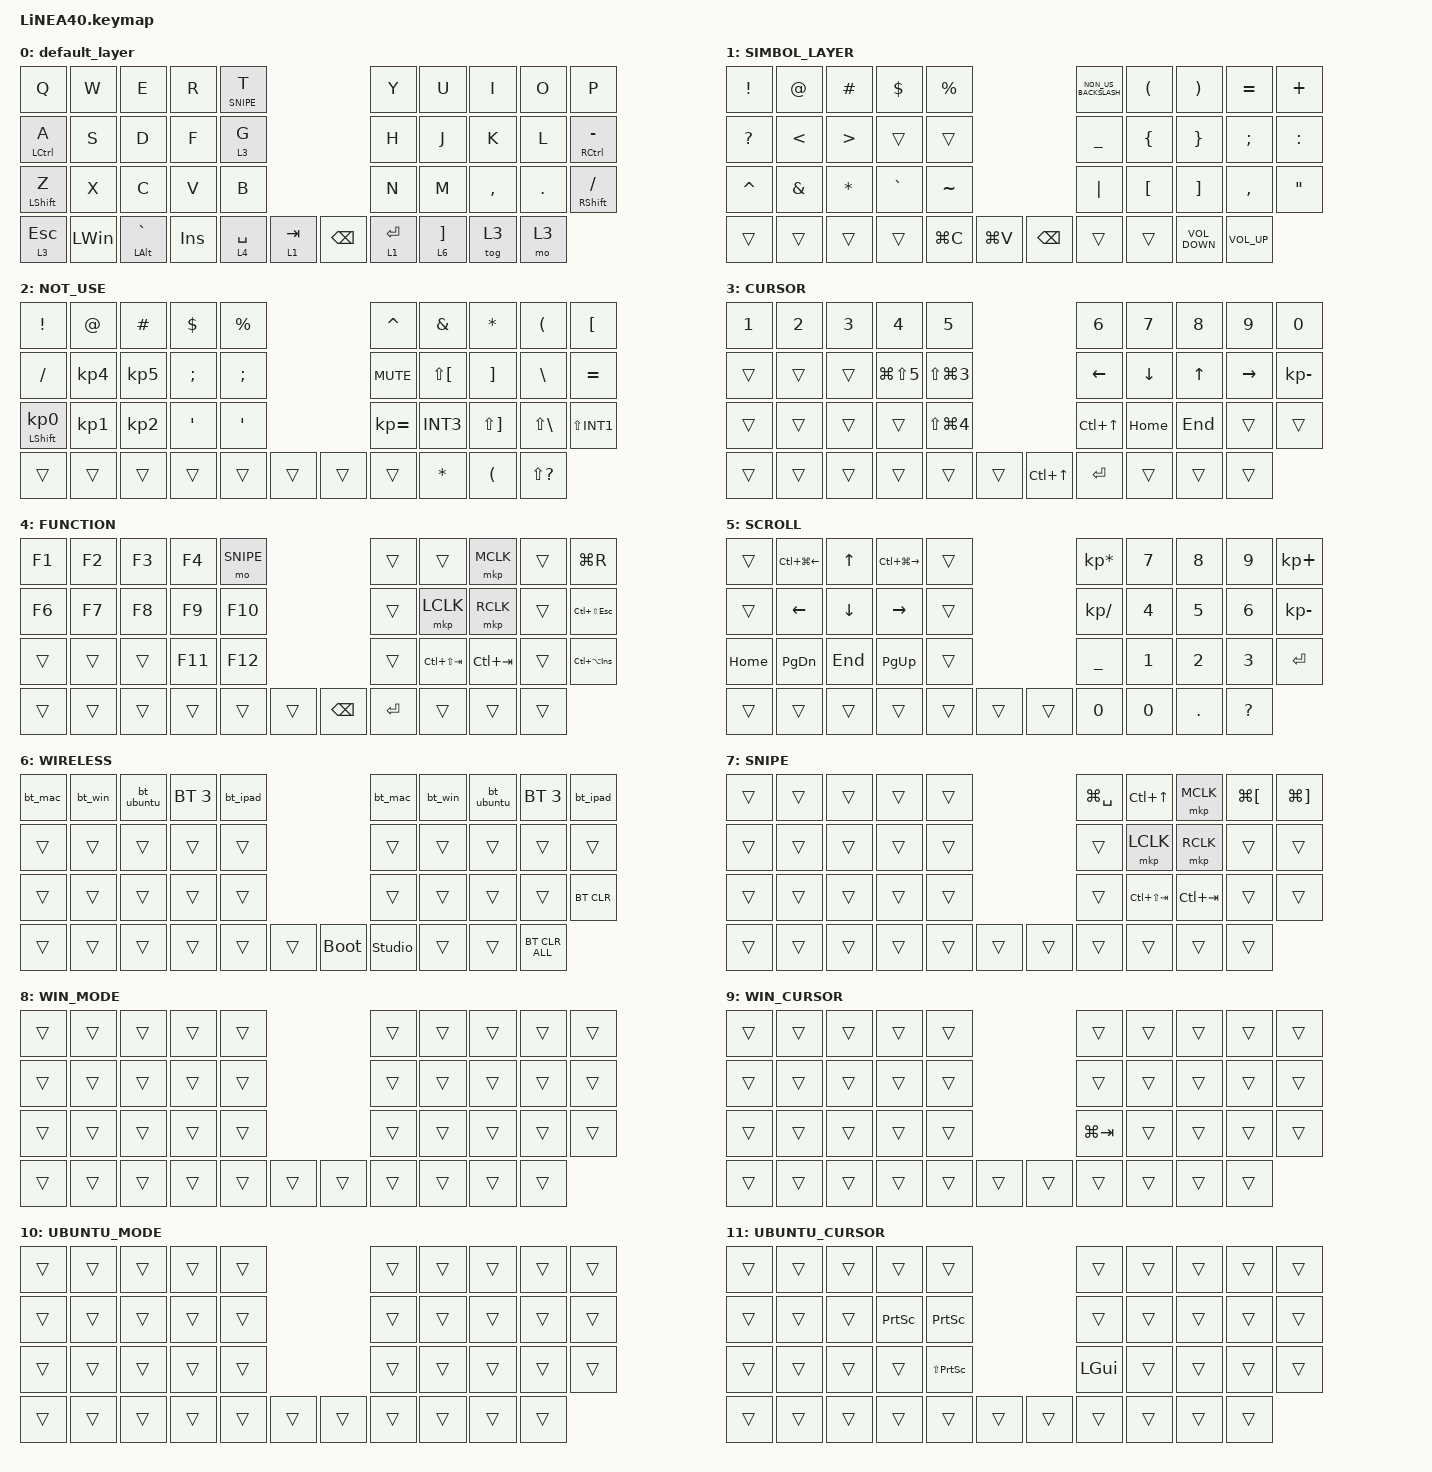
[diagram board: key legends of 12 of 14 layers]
#define ZMK_POINTING_DEFAULT_SCRL_VAL 150

#include <dt-bindings/zmk/input_transform.h>
#include <input/processors.dtsi>
#include <input/processors/runtime-input-processor.dtsi>
#include <zephyr/dt-bindings/input/input-event-codes.h>
#include <behaviors.dtsi>
#include <dt-bindings/zmk/bt.h>
#include <dt-bindings/zmk/keys.h>
#include <dt-bindings/zmk/pointing.h>

#define MOUSE 1
#define MARK 2
#define CURSOR 3
#define FUNCTION 4
#define SCROLL 5
#define WIRELESS 6
#define SNIPE 7
#define WIN_MODE 8
#define WIN_CURSOR 9
#define UBUNTU_MODE 10
#define UBUNTU_CURSOR 11
#define IPAD_MODE 12
#define IPAD_CURSOR 13

&mt { tapping-term-ms = <150>; };

//mouse cursol

&mmv {
    delay-ms = <20>;
    trigger-period-ms = <5>;
    time-to-max-speed-ms = <100>;
    acceleration-exponent = <2>;
};

//mouse scroll

&msc {
    delay-ms = <3>;
    trigger-period-ms = <3>;
    time-to-max-speed-ms = <100>;
    acceleration-exponent = <0>;
};

/ {
    input_processors {
        zip_wheel_scaler: zip_wheel_scaler {
            compatible = "zmk,input-processor-scaler";
            #input-processor-cells = <2>;
            type = <INPUT_EV_REL>;
            codes = <INPUT_REL_WHEEL>;
            track-remainders;
        };

        zip_trackball_scroller_scaler: zip_trackball_scroller_scaler {
            compatible = "zmk,input-processor-scaler";
            #input-processor-cells = <2>;
            type = <INPUT_EV_REL>;
            codes = <INPUT_REL_X>, <INPUT_REL_Y>;

            track-remainders;
        };

        zip_snipe_scaler: zip_snipe_scaler {
            compatible = "zmk,input-processor-scaler";
            #input-processor-cells = <2>;
            type = <INPUT_EV_REL>;
            codes = <INPUT_REL_X>, <INPUT_REL_Y>;
            track-remainders;
        };
    };
};

&msc_input_listener {
    speed_up {
        layers = <FUNCTION>;
        input-processors = <&zip_wheel_scaler 3 1>; //スクロールを3倍速にする
    };
};

&mouse_runtime_input_processor {
    temp-layer-enabled;
    temp-layer = <FUNCTION>;
};

&scroll_runtime_input_processor {
    active-layers = <(BIT(CURSOR) | BIT(SCROLL) | BIT(FUNCTION))>;
    xy-to-scroll-enabled;
};

&trackball_listener {
    snipe {
        layers = <SNIPE>;
        input-processors = <&zip_snipe_scaler 1 4>;
    };

    scroller {
        layers = <CURSOR SCROLL>;
        input-processors =
            <&zip_xy_transform INPUT_TRANSFORM_Y_INVERT>,
            //スクロール方向を逆転,,,,,,,
            <&zip_trackball_scroller_scaler 1 15>,
            <&zip_xy_to_scroll_mapper>;
    };
};

/ {
    combos {
        compatible = "zmk,combos";

        ZenkakuHankaku {
            bindings = <&kp LANG_ZENKAKUHANKAKU>;
            key-positions = <11 12>;
        };

        DeleteKey {
            bindings = <&kp DEL>;
            key-positions = <7 8>;
        };

        InsertKey {
            bindings = <&kp INS>;
            key-positions = <6 7>;
        };

        left-ctrl {
            bindings = <&kp LEFT_CONTROL>;
            key-positions = <10 11>;
        };

        ToggleIME {
            bindings = <&kp LC(SPACE)>;
            key-positions = <8 9>;
            layers = <0 1 2 3 4 5 6 7 8 9 10 11>;
        };

        ToggleIME_iPad {
            bindings = <&kp C_AC_NEXT_KEYBOARD_LAYOUT_SELECT>;
            key-positions = <8 9>;
            layers = <IPAD_MODE>;
        };

        MomentaryCursor {
            bindings = <&mo 3>;
            key-positions = <3 4>;
        };
    };

    conditional_layers {
        compatible = "zmk,conditional-layers";

        win_cursor_condition {
            if-layers = <CURSOR WIN_MODE>;
            then-layer = <WIN_CURSOR>;
        };

        ubuntu_cursor_condition {
            if-layers = <CURSOR UBUNTU_MODE>;
            then-layer = <UBUNTU_CURSOR>;
        };

        ipad_cursor_condition {
            if-layers = <CURSOR IPAD_MODE>;
            then-layer = <IPAD_CURSOR>;
        };
    };

    macros {
        toggle_ime: toggle_ime {
            compatible = "zmk,behavior-macro";
            #binding-cells = <0>;
            bindings = <&kp LC(SPACE)>;
        };

        bt_mac: bt_mac {
            compatible = "zmk,behavior-macro";
            #binding-cells = <0>;
            wait-ms = <100>;
            tap-ms = <100>;
            bindings = <&bt BT_SEL 0 &to 0>;
        };

        bt_win: bt_win {
            compatible = "zmk,behavior-macro";
            #binding-cells = <0>;
            wait-ms = <100>;
            tap-ms = <100>;
            bindings = <&bt BT_SEL 1 &tog WIN_MODE>;
        };

        bt_ubuntu: bt_ubuntu {
            compatible = "zmk,behavior-macro";
            #binding-cells = <0>;
            wait-ms = <100>;
            tap-ms = <100>;
            bindings = <&bt BT_SEL 2 &tog UBUNTU_MODE>;
        };

        bt_ipad: bt_ipad {
            compatible = "zmk,behavior-macro";
            #binding-cells = <0>;
            wait-ms = <100>;
            tap-ms = <100>;
            bindings = <&bt BT_SEL 4 &tog IPAD_MODE>;
        };

        globe_up: globe_up {
            compatible = "zmk,behavior-macro";
            #binding-cells = <0>;
            bindings =
                <&macro_press &kp C_AC_NEXT_KEYBOARD_LAYOUT_SELECT>,
                <&macro_tap &kp UP_ARROW>,
                <&macro_release &kp C_AC_NEXT_KEYBOARD_LAYOUT_SELECT>;
        };

    };

    behaviors {
        mt_hp: mod_tap_hold_preferred {
            compatible = "zmk,behavior-hold-tap";
            #binding-cells = <2>;
            flavor = "hold-preferred";
            tapping-term-ms = <150>;
            bindings = <&kp>, <&kp>;
        };

        mt_bal: mod_tap_balanced {
            compatible = "zmk,behavior-hold-tap";
            #binding-cells = <2>;
            flavor = "balanced";
            tapping-term-ms = <200>;
            quick-tap-ms = <175>;
            require-prior-idle-ms = <125>;
            bindings = <&kp>, <&kp>;
        };

        lt_hp: layer_tap_hold_preferred {
            compatible = "zmk,behavior-hold-tap";
            #binding-cells = <2>;
            flavor = "balanced";
            tapping-term-ms = <150>;
            quick-tap-ms = <150>;
            bindings = <&mo>, <&kp>;
        };

        lt_ime: layer_tap_ime {
            compatible = "zmk,behavior-hold-tap";
            #binding-cells = <2>;
            flavor = "balanced";
            tapping-term-ms = <150>;
            quick-tap-ms = <150>;
            bindings = <&mo>, <&toggle_ime>;
        };

        re_kp: sensor_rotate_kp {
            compatible = "zmk,behavior-sensor-rotate-var";
            #sensor-binding-cells = <2>;
            bindings = <&kp>, <&kp>;
        };

        mouse_scrl: mouse_wheel_scrl {
            compatible = "zmk,behavior-sensor-rotate-var";
            #sensor-binding-cells = <2>;
            bindings = <&msc>, <&msc>;

            tap-ms = <20>;
        };
    };

    keymap {
        compatible = "zmk,keymap";

        default_layer {
            bindings = <
&kp Q             &kp W         &kp E               &kp R    &lt_hp SNIPE T                              &kp Y        &kp U    &kp I                &kp O           &kp P
&mt_bal LCTRL A    &kp S         &kp D               &kp F    &lt_hp 3 G                                    &kp H        &kp J    &kp K                &kp L           &mt_bal RIGHT_CONTROL MINUS
&mt_bal LEFT_SHIFT Z  &kp X         &kp C               &kp V    &kp B                                    &kp N        &kp M    &kp COMMA            &kp DOT         &mt_bal RIGHT_SHIFT SLASH
&lt 3 ESC         &kp LEFT_WIN  &mt LEFT_ALT GRAVE  &kp INS  &lt 4 SPACE  &lt 1 TAB    &kp BACKSPACE  &lt 1 ENTER           &lt 6 RIGHT_BRACKET  &tog 3  &mo 3
            >;

            sensor-bindings = <&mouse_scrl SCRL_DOWN SCRL_UP>;
        };

        //1

        SIMBOL_LAYER {
            bindings = <
&kp EXCLAMATION  &kp AT_SIGN    &kp HASH          &kp DOLLAR  &kp PERCENT                              &kp NON_US_BACKSLASH  &kp LEFT_PARENTHESIS  &kp RIGHT_PARENTHESIS  &kp EQUAL          &kp PLUS
&kp QUESTION     &kp LESS_THAN  &kp GREATER_THAN  &trans      &trans                                   &kp UNDERSCORE        &kp LEFT_BRACE        &kp RIGHT_BRACE        &kp SEMICOLON      &kp COLON
&kp CARET        &kp AMPERSAND  &kp ASTERISK      &kp GRAVE   &kp TILDE                                &kp PIPE              &kp LEFT_BRACKET      &kp RIGHT_BRACKET      &kp COMMA          &kp DOUBLE_QUOTES
&trans           &trans         &trans            &trans      &kp LG(C)    &kp LG(V)    &kp BACKSPACE  &trans                                      &trans                 &kp C_VOLUME_DOWN  &kp C_VOLUME_UP
            >;
        };

        //2

        NOT_USE {
            bindings = <
&kp EXCLAMATION             &kp AT           &kp HASH         &kp DOLLAR     &kp PERCENT                      &kp CARET     &kp AMPERSAND  &kp ASTERISK           &kp LEFT_PARENTHESIS  &kp LBKT
&kp SLASH                   &kp KP_NUMBER_4  &kp KP_NUMBER_5  &kp SEMICOLON  &kp SEMICOLON                    &kp C_MUTE    &kp LS(LBKT)   &kp RIGHT_BRACKET      &kp BACKSLASH         &kp EQUAL
&mt LEFT_SHIFT KP_NUMBER_0  &kp KP_NUMBER_1  &kp KP_NUMBER_2  &kp APOS       &kp SQT                          &kp KP_EQUAL  &kp INT3       &kp LS(RIGHT_BRACKET)  &kp LS(BACKSLASH)     &kp LS(INT1)
&trans                      &trans           &trans           &trans         &trans         &trans    &trans  &trans                       &kp ASTERISK           &kp LEFT_PARENTHESIS  &kp LS(QUESTION)
            >;

            sensor-bindings = <&re_kp C_VOLUME_DOWN C_VOLUME_UP>;
        };

        //3

        CURSOR {
            bindings = <
&kp NUMBER_1  &kp NUMBER_2  &kp NUMBER_3  &kp NUMBER_4          &kp NUMBER_5                                      &kp NUMBER_6      &kp NUMBER_7  &kp NUMBER_8  &kp NUMBER_9  &kp NUMBER_0
&trans        &trans        &trans        &kp LG(LS(NUMBER_5))  &kp LS(LG(NUMBER_3))                              &kp LEFT          &kp DOWN      &kp UP_ARROW  &kp RIGHT     &kp KP_MINUS
&trans        &trans        &trans        &trans                &kp LS(LG(NUMBER_4))                              &kp LC(UP_ARROW)  &kp HOME      &kp END       &trans        &trans
&trans        &trans        &trans        &trans                &trans                &trans    &kp LC(UP_ARROW)  &kp ENTER                       &trans        &trans        &trans
            >;
        };

        //4

        FUNCTION {
            bindings = <
&kp F1  &kp F2  &kp F3  &kp F4   &mo SNIPE                         &trans     &trans           &mkp MCLK    &trans  &kp LG(R)
&kp F6  &kp F7  &kp F8  &kp F9   &kp F10                           &trans     &mkp LCLK        &mkp RCLK    &trans  &kp LC(LS(ESCAPE))
&trans  &trans  &trans  &kp F11  &kp F12                           &trans     &kp LC(LS(TAB))  &kp LC(TAB)  &trans  &kp LC(LA(INS))
&trans  &trans  &trans  &trans   &trans   &trans    &kp BACKSPACE  &kp ENTER                   &trans       &trans  &trans
            >;

            sensor-bindings = <&mouse_scrl SCRL_DOWN SCRL_UP>;
        };

        //5

        SCROLL {
            bindings = <
&trans    &kp LC(LG(LEFT_ARROW))  &kp UP_ARROW  &kp LC(LG(RIGHT_ARROW))  &trans                    &kp KP_MULTIPLY  &kp NUMBER_7  &kp NUMBER_8  &kp NUMBER_9  &kp KP_PLUS
&trans    &kp LEFT_ARROW          &kp DOWN      &kp RIGHT_ARROW          &trans                    &kp KP_SLASH     &kp NUMBER_4  &kp NUMBER_5  &kp NUMBER_6  &kp KP_MINUS
&kp HOME  &kp PAGE_DOWN           &kp END       &kp PAGE_UP              &trans                    &kp UNDER        &kp NUMBER_1  &kp NUMBER_2  &kp NUMBER_3  &kp ENTER
&trans    &trans                  &trans        &trans                   &trans  &trans    &trans  &kp NUMBER_0                   &kp NUMBER_0  &kp DOT       &kp QUESTION
            >;

            sensor-bindings = <&inc_dec_kp DOWN_ARROW UP_ARROW>;
        };

        //6

        WIRELESS {
            bindings = <
&bt_mac       &bt_win       &bt_ubuntu    &bt BT_SEL 3  &bt_ipad                         &bt_mac         &bt_win       &bt_ubuntu    &bt BT_SEL 3  &bt_ipad
&trans        &trans        &trans        &trans        &trans                               &trans          &trans        &trans        &trans        &trans
&trans        &trans        &trans        &trans        &trans                               &trans          &trans        &trans        &trans        &bt BT_CLR
&trans        &trans        &trans        &trans        &trans        &trans    &bootloader  &studio_unlock                &trans        &trans        &bt BT_CLR_ALL
            >;

            sensor-bindings = <&inc_dec_kp RIGHT_ARROW LEFT_ARROW>;
        };

        //7

        SNIPE {
            bindings = <
&trans  &trans  &trans  &trans  &trans                    &kp LG(SPACE)  &kp LC(UP_ARROW)  &mkp MCLK    &kp LG(LEFT_BRACKET)  &kp LG(RIGHT_BRACKET)
&trans  &trans  &trans  &trans  &trans                    &trans         &mkp LCLK         &mkp RCLK    &trans  &trans
&trans  &trans  &trans  &trans  &trans                    &trans         &kp LC(LS(TAB))   &kp LC(TAB)  &trans  &trans
&trans  &trans  &trans  &trans  &trans  &trans    &trans  &trans                           &trans       &trans  &trans
            >;
        };

        //8 Windows mode flag (all transparent, used as conditional layer trigger)

        WIN_MODE {
            bindings = <
&trans  &trans  &trans  &trans  &trans                    &trans  &trans  &trans  &trans  &trans
&trans  &trans  &trans  &trans  &trans                    &trans  &trans  &trans  &trans  &trans
&trans  &trans  &trans  &trans  &trans                    &trans  &trans  &trans  &trans  &trans
&trans  &trans  &trans  &trans  &trans  &trans    &trans  &trans          &trans  &trans  &trans
            >;
        };

        //9 Conditional: CURSOR + WIN_MODE -> override Mission Control to Win+Tab

        WIN_CURSOR {
            bindings = <
&trans  &trans  &trans  &trans  &trans                            &trans        &trans    &trans  &trans  &trans
&trans  &trans  &trans  &trans  &trans                            &trans        &trans    &trans  &trans  &trans
&trans  &trans  &trans  &trans  &trans                            &kp LG(TAB)  &trans    &trans  &trans  &trans
&trans  &trans  &trans  &trans  &trans  &trans    &trans         &trans                  &trans  &trans  &trans
            >;
        };

        //10 Ubuntu mode flag (all transparent, used as conditional layer trigger)

        UBUNTU_MODE {
            bindings = <
&trans  &trans  &trans  &trans  &trans                    &trans  &trans  &trans  &trans  &trans
&trans  &trans  &trans  &trans  &trans                    &trans  &trans  &trans  &trans  &trans
&trans  &trans  &trans  &trans  &trans                    &trans  &trans  &trans  &trans  &trans
&trans  &trans  &trans  &trans  &trans  &trans    &trans  &trans          &trans  &trans  &trans
            >;
        };

        //11 Conditional: CURSOR + UBUNTU_MODE -> override Mac keys for Ubuntu

        UBUNTU_CURSOR {
            bindings = <
&trans  &trans  &trans  &trans      &trans                                &trans     &trans    &trans  &trans  &trans
&trans  &trans  &trans  &kp PSCRN   &kp PSCRN                             &trans     &trans    &trans  &trans  &trans
&trans  &trans  &trans  &trans      &kp LS(PSCRN)                         &kp LGUI   &trans    &trans  &trans  &trans
&trans  &trans  &trans  &trans      &trans         &trans    &trans       &trans                &trans  &trans  &trans
            >;
        };

        //12 iPad mode flag (all transparent, used for combo override)

        IPAD_MODE_LAYER {
            bindings = <
&trans  &trans  &trans  &trans  &trans                    &trans  &trans  &trans  &trans  &trans
&trans  &trans  &trans  &trans  &trans                    &trans  &trans  &trans  &trans  &trans
&trans  &trans  &trans  &trans  &trans                    &trans  &trans  &trans  &trans  &trans
&trans  &trans  &trans  &trans  &trans  &trans    &trans  &trans          &trans  &trans  &trans
            >;
        };

        //13 Conditional: CURSOR + IPAD_MODE -> override Mission Control to Globe+Up (App Switcher)

        IPAD_CURSOR {
            bindings = <
&trans  &trans  &trans  &trans  &trans                            &trans       &trans    &trans  &trans  &trans
&trans  &trans  &trans  &trans  &trans                            &trans       &trans    &trans  &trans  &trans
&trans  &trans  &trans  &trans  &trans                            &globe_up    &trans    &trans  &trans  &trans
&trans  &trans  &trans  &trans  &trans  &trans    &globe_up      &trans                 &trans  &trans  &trans
            >;
        };
    };
};
